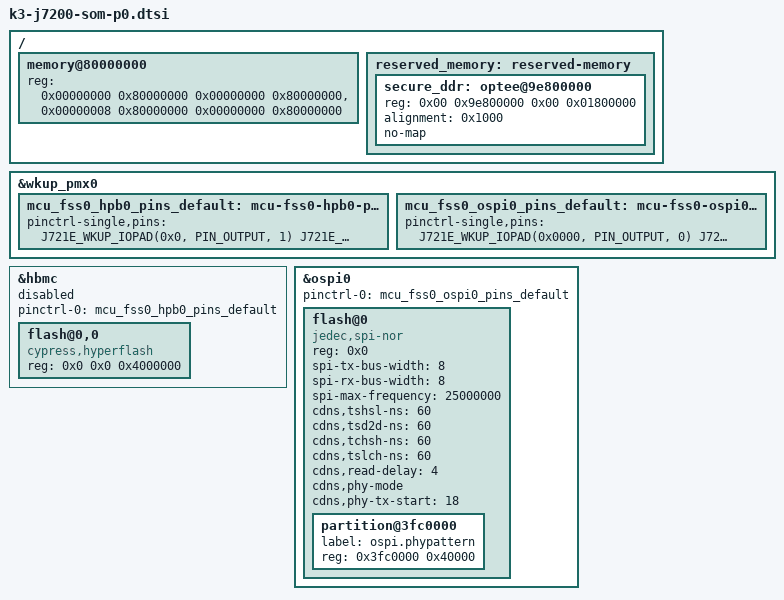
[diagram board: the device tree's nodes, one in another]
// SPDX-License-Identifier: GPL-2.0
/*
 * Copyright (C) 2020 Texas Instruments Incorporated - https://www.ti.com/
 */

/dts-v1/;

#include "k3-j7200.dtsi"

/ {
	memory@80000000 {
		device_type = "memory";
		/* 4G RAM */
		reg = <0x00000000 0x80000000 0x00000000 0x80000000>,
		      <0x00000008 0x80000000 0x00000000 0x80000000>;
	};

	reserved_memory: reserved-memory {
		#address-cells = <2>;
		#size-cells = <2>;
		ranges;

		secure_ddr: optee@9e800000 {
			reg = <0x00 0x9e800000 0x00 0x01800000>;
			alignment = <0x1000>;
			no-map;
		};
	};
};

&wkup_pmx0 {
	mcu_fss0_hpb0_pins_default: mcu-fss0-hpb0-pins-default {
		pinctrl-single,pins = <
			J721E_WKUP_IOPAD(0x0, PIN_OUTPUT, 1) /* (B6) MCU_OSPI0_CLK.MCU_HYPERBUS0_CK */
			J721E_WKUP_IOPAD(0x4, PIN_OUTPUT, 1) /* (C8) MCU_OSPI0_LBCLKO.MCU_HYPERBUS0_CKn */
			J721E_WKUP_IOPAD(0x2c, PIN_OUTPUT, 1) /* (D6) MCU_OSPI0_CSn0.MCU_HYPERBUS0_CSn0 */
			J721E_WKUP_IOPAD(0x30, PIN_OUTPUT, 1) /* (D7) MCU_OSPI0_CSn1.MCU_HYPERBUS0_RESETn */
			J721E_WKUP_IOPAD(0x8, PIN_INPUT, 1) /* (B7) MCU_OSPI0_DQS.MCU_HYPERBUS0_RWDS */
			J721E_WKUP_IOPAD(0xc, PIN_INPUT, 1) /* (D8) MCU_OSPI0_D0.MCU_HYPERBUS0_DQ0 */
			J721E_WKUP_IOPAD(0x10, PIN_INPUT, 1) /* (C7) MCU_OSPI0_D1.MCU_HYPERBUS0_DQ1 */
			J721E_WKUP_IOPAD(0x14, PIN_INPUT, 1) /* (C5) MCU_OSPI0_D2.MCU_HYPERBUS0_DQ2 */
			J721E_WKUP_IOPAD(0x18, PIN_INPUT, 1) /* (A5) MCU_OSPI0_D3.MCU_HYPERBUS0_DQ3 */
			J721E_WKUP_IOPAD(0x1c, PIN_INPUT, 1) /* (A6) MCU_OSPI0_D4.MCU_HYPERBUS0_DQ4 */
			J721E_WKUP_IOPAD(0x20, PIN_INPUT, 1) /* (B8) MCU_OSPI0_D5.MCU_HYPERBUS0_DQ5 */
			J721E_WKUP_IOPAD(0x24, PIN_INPUT, 1) /* (A8) MCU_OSPI0_D6.MCU_HYPERBUS0_DQ6 */
			J721E_WKUP_IOPAD(0x28, PIN_INPUT, 1) /* (A7) MCU_OSPI0_D7.MCU_HYPERBUS0_DQ7 */
		>;
	};

	mcu_fss0_ospi0_pins_default: mcu-fss0-ospi0-pins-default {
		pinctrl-single,pins = <
			J721E_WKUP_IOPAD(0x0000, PIN_OUTPUT, 0) /* MCU_OSPI0_CLK */
			J721E_WKUP_IOPAD(0x002c, PIN_OUTPUT, 0) /* MCU_OSPI0_CSn0 */
			J721E_WKUP_IOPAD(0x000c, PIN_INPUT, 0)  /* MCU_OSPI0_D0 */
			J721E_WKUP_IOPAD(0x0010, PIN_INPUT, 0)  /* MCU_OSPI0_D1 */
			J721E_WKUP_IOPAD(0x0014, PIN_INPUT, 0)  /* MCU_OSPI0_D2 */
			J721E_WKUP_IOPAD(0x0018, PIN_INPUT, 0)  /* MCU_OSPI0_D3 */
			J721E_WKUP_IOPAD(0x001c, PIN_INPUT, 0)  /* MCU_OSPI0_D4 */
			J721E_WKUP_IOPAD(0x0020, PIN_INPUT, 0)  /* MCU_OSPI0_D5 */
			J721E_WKUP_IOPAD(0x0024, PIN_INPUT, 0)  /* MCU_OSPI0_D6 */
			J721E_WKUP_IOPAD(0x0028, PIN_INPUT, 0)  /* MCU_OSPI0_D7 */
			J721E_WKUP_IOPAD(0x0008, PIN_INPUT_PULLDOWN, 0)  /* MCU_OSPI0_DQS */
		>;
	};
};

&hbmc {
	status = "disabled";
	pinctrl-names = "default";
	pinctrl-0 = <&mcu_fss0_hpb0_pins_default>;
	ranges = <0x0 0x0 0x5 0x0 0x4000000>, /* 64MB Flash on CS0 */
		 <0x1 0x0 0x5 0x4000000 0x800000>; /* 8MB RAM on CS1 */

	flash@0,0 {
		compatible = "cypress,hyperflash", "cfi-flash";
		reg = <0x0 0x0 0x4000000>;
	};
};

&ospi0 {
	pinctrl-names = "default";
	pinctrl-0 = <&mcu_fss0_ospi0_pins_default>;

	flash@0{
		compatible = "jedec,spi-nor";
		reg = <0x0>;
		spi-tx-bus-width = <8>;
		spi-rx-bus-width = <8>;
		spi-max-frequency = <25000000>;
		cdns,tshsl-ns = <60>;
		cdns,tsd2d-ns = <60>;
		cdns,tchsh-ns = <60>;
		cdns,tslch-ns = <60>;
		cdns,read-delay = <4>;
		cdns,phy-mode;
		cdns,phy-tx-start = <18>;
		#address-cells = <1>;
		#size-cells = <1>;
		partition@3fc0000 {
			label = "ospi.phypattern";
			reg = <0x3fc0000 0x40000>;
			u-boot,dm-spl;
		};
	};
};
